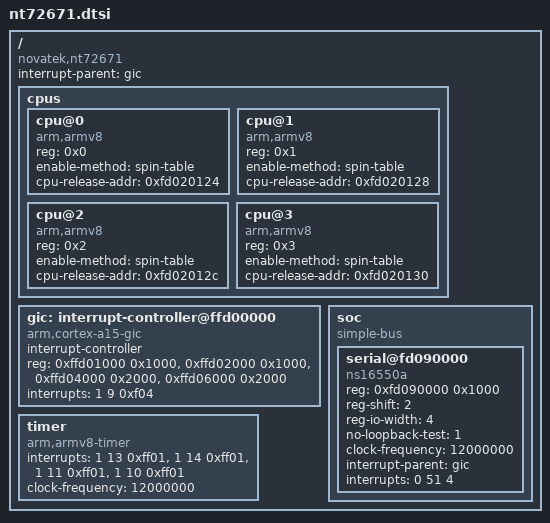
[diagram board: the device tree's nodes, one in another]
/*
 * dts file for Novatek NT72671 SoC
 *
 * Copyright (C) 2014, Novatek Microelectronics Corp.
 *
 * This program is free software; you can redistribute it and/or
 * modify it under the terms of the GNU General Public License as
 * published by the Free Software Foundation; either version 2 of
 * the License, or (at your option) any later version.
 */

/ {
	compatible = "novatek,nt72671";
	interrupt-parent = <&gic>;
	#address-cells = <1>;
	#size-cells = <1>;

	cpus {
		#address-cells = <1>;
		#size-cells = <0>;

		cpu@0 {
			device_type = "cpu";
			compatible = "arm,armv8";
			reg = <0x0>;
			enable-method = "spin-table";
			cpu-release-addr = <0xfd020124>;
		};

		cpu@1 {
			device_type = "cpu";
			compatible = "arm,armv8";
			reg = <0x1>;
			enable-method = "spin-table";
			cpu-release-addr = <0xfd020128>;
		};

		cpu@2 {
			device_type = "cpu";
			compatible = "arm,armv8";
			reg = <0x2>;
			enable-method = "spin-table";
			cpu-release-addr = <0xfd02012c>;
		};

		cpu@3 {
			device_type = "cpu";
			compatible = "arm,armv8";
			reg = <0x3>;
			enable-method = "spin-table";
			cpu-release-addr = <0xfd020130>;
		};
	};

	gic: interrupt-controller@ffd00000 {
		compatible = "arm,cortex-a15-gic";
		#interrupt-cells = <3>;
		interrupt-controller;
		reg =	<0xffd01000 0x1000>,		/* GIC Dist */
				<0xffd02000 0x1000>,		/* GIC CPU */
				<0xffd04000 0x2000>,		/* GIC VCPU Control */
				<0xffd06000 0x2000>;		/* GIC VCPU */
		interrupts = <1 9 0xf04>;			/* GIC Maintenence IRQ */
	};

	timer {
		compatible = "arm,armv8-timer";
		interrupts =	<1 13 0xff01>,		/* Secure Phys IRQ */
						<1 14 0xff01>,		/* Non-secure Phys IRQ */
						<1 11 0xff01>,		/* Virt IRQ */
						<1 10 0xff01>;		/* Hyp IRQ */
		clock-frequency = <12000000>;
	};

	soc {
		compatible = "simple-bus";
		#address-cells = <1>;
		#size-cells = <1>;
		ranges;

		serial@fd090000 {
			device_type = "serial";
			compatible = "ns16550a";
			reg = <0xfd090000 0x1000>;
			reg-shift = <2>;
			reg-io-width = <4>;
			no-loopback-test = <1>;
			clock-frequency = <12000000>;
			interrupt-parent = <&gic>;
			interrupts = <0 51 4>;
		};
	};
};
